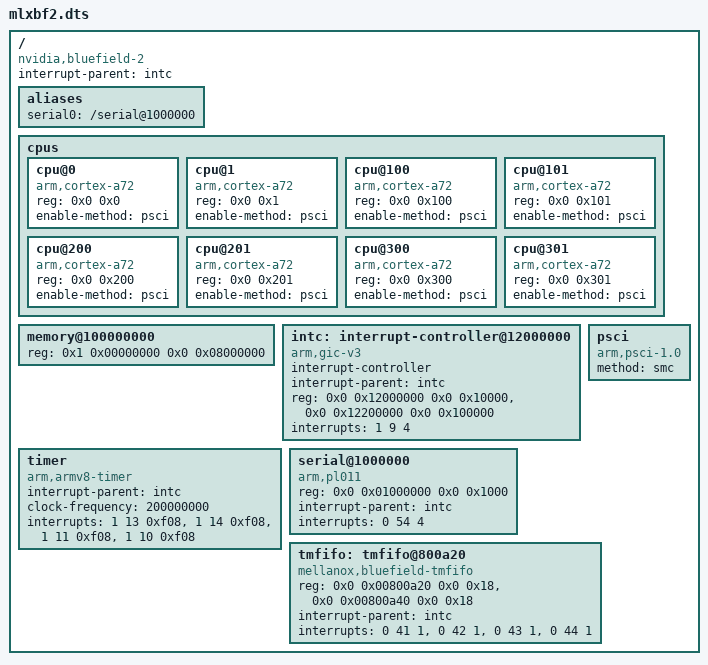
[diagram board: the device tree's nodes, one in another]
/*
 * Copyright 2026, PhD Research Project
 *
 * SPDX-License-Identifier: GPL-2.0-only
 *
 * Minimal seL4 device tree for NVIDIA BlueField-2.
 *
 * Local evidence:
 *   - original/bf2-dump/dmesg-full.txt
 *   - original/bf2-dump/iomem.txt
 *   - original/bf2-dump/interrupts.txt
 *
 * Hardware facts:
 *   CPU: 8x Cortex-A72
 *   DRAM: starts at 0x80000000
 *   GICv3: distributor @ 0x12000000, redistributors @ 0x12200000
 *   Timer: ARM generic timer @ 200 MHz
 *   Console: PL011-compatible UART @ 0x01000000, SPI 54
 *   Boot: PSCI v1.1 via SMC, UEFI enters Linux at EL2 on this device
 */

/dts-v1/;

/ {
	compatible = "nvidia,bluefield-2", "mellanox,bluefield-2";
	#address-cells = <2>;
	#size-cells = <2>;
	interrupt-parent = <&intc>;

	aliases {
		serial0 = "/serial@1000000";
	};

	cpus {
		#address-cells = <2>;
		#size-cells = <0>;

		cpu@0 {
			compatible = "arm,cortex-a72";
			device_type = "cpu";
			reg = <0x0 0x0>;
			enable-method = "psci";
		};

		cpu@1 {
			compatible = "arm,cortex-a72";
			device_type = "cpu";
			reg = <0x0 0x1>;
			enable-method = "psci";
		};

		cpu@100 {
			compatible = "arm,cortex-a72";
			device_type = "cpu";
			reg = <0x0 0x100>;
			enable-method = "psci";
		};

		cpu@101 {
			compatible = "arm,cortex-a72";
			device_type = "cpu";
			reg = <0x0 0x101>;
			enable-method = "psci";
		};

		cpu@200 {
			compatible = "arm,cortex-a72";
			device_type = "cpu";
			reg = <0x0 0x200>;
			enable-method = "psci";
		};

		cpu@201 {
			compatible = "arm,cortex-a72";
			device_type = "cpu";
			reg = <0x0 0x201>;
			enable-method = "psci";
		};

		cpu@300 {
			compatible = "arm,cortex-a72";
			device_type = "cpu";
			reg = <0x0 0x300>;
			enable-method = "psci";
		};

		cpu@301 {
			compatible = "arm,cortex-a72";
			device_type = "cpu";
			reg = <0x0 0x301>;
			enable-method = "psci";
		};
	};

	memory@100000000 {
		device_type = "memory";
		/* Use high RAM; BF2 UEFI faults when the EFI loader writes the DTB
		 * into the low 0x80000000 window during rshim live boot. */
		reg = <0x1 0x00000000 0x0 0x08000000>;
	};

	intc: interrupt-controller@12000000 {
		compatible = "arm,gic-v3";
		#interrupt-cells = <3>;
		#address-cells = <2>;
		#size-cells = <2>;
		ranges;
		interrupt-controller;
		interrupt-parent = <&intc>;
		reg = <0x0 0x12000000 0x0 0x10000>,
		      <0x0 0x12200000 0x0 0x100000>;
		interrupts = <1 9 4>;
	};

	timer {
		compatible = "arm,armv8-timer";
		interrupt-parent = <&intc>;
		clock-frequency = <200000000>;
		interrupts = <1 13 0xf08>,
		             <1 14 0xf08>,
		             <1 11 0xf08>,
		             <1 10 0xf08>;
	};

	psci {
		compatible = "arm,psci-1.0", "arm,psci-0.2";
		method = "smc";
	};

	serial@1000000 {
		compatible = "arm,pl011", "arm,primecell";
		reg = <0x0 0x01000000 0x0 0x1000>;
		interrupt-parent = <&intc>;
		interrupts = <0 54 4>;
	};

	tmfifo: tmfifo@800a20 {
		compatible = "mellanox,bluefield-tmfifo";
		reg = <0x0 0x00800a20 0x0 0x18>,
		      <0x0 0x00800a40 0x0 0x18>;
		interrupt-parent = <&intc>;
		interrupts = <0 41 1>,
		             <0 42 1>,
		             <0 43 1>,
		             <0 44 1>;
	};
};
